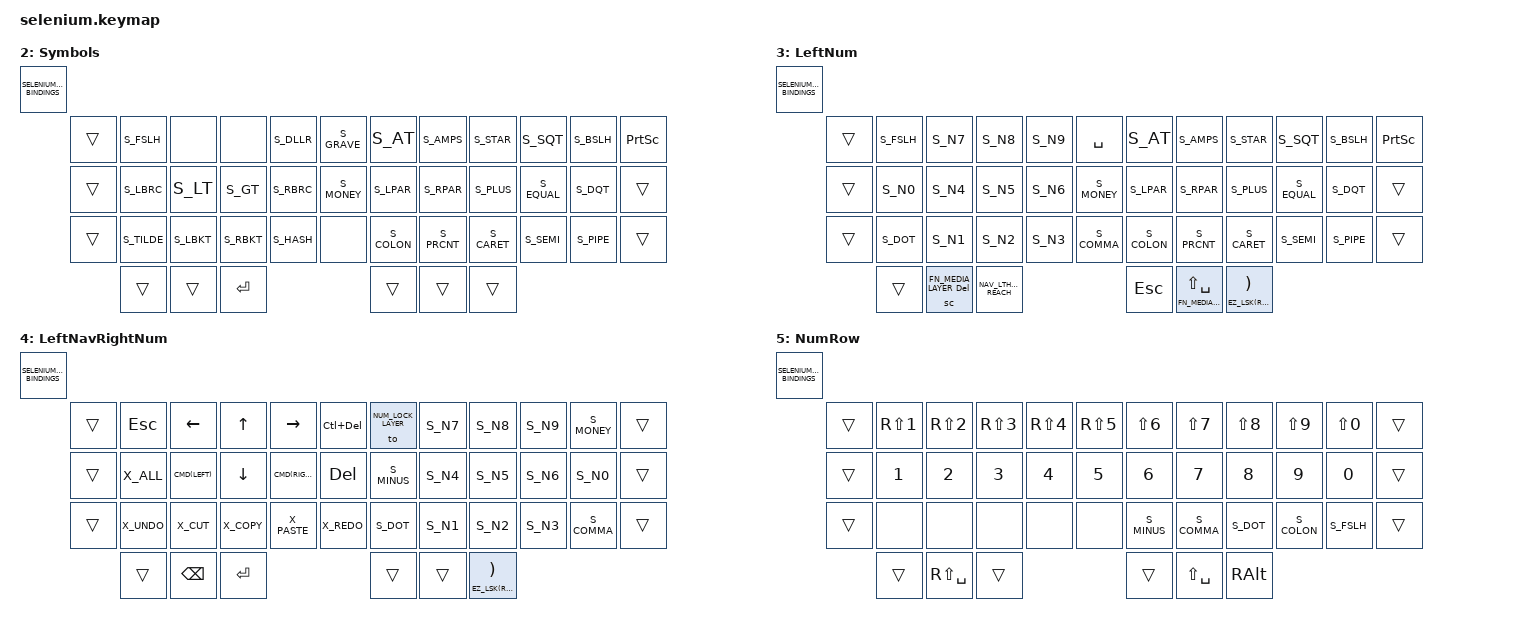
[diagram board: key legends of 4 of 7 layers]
// Selenium keymap:
// https://github.com/OneDeadKey/selenium

#include <dt-bindings/zmk/bt.h> // bluetooth behaviors (see fn/media layer)

#ifndef CI_IGNORE_USER_SETTINGS
  #include "settings.h"   // user settings
#endif

#include "defaults.h"     // default options and safeguards
#include "aliases.h"      // defines symbols and actions
#include "bindings.h"     // default SELENIUM_KEYMAP_BINDINGS macro
#include "mappings.dtsi"  // key mapping helpers and macros
#include "hold_taps.dtsi" // defines thumb keys and homerow mods

/**
 * All keyboard layers are defined by blocks on a 42-key basis, as follows:
 *
 *   <SELENIUM_KEYMAP_BINDINGS(
 *     Tab   , QWERT , YUIOP , BkSpc ,
 *     Esc   , ASDFG , HJKL: , Enter ,
 *     Shift , ZXCVB , NM<>? , Shift ,
 *      LT1, LT2, LT3, RT3, RT2, RT1
 *   )>
 *
 * Where LTx/RTx are the left/right thumb keys.
 * Beware: missing or misplacing a comma in the definitions below would break the keymap.
 */

/ {
  keymap {
    compatible = "zmk,keymap";

    // 0. Base layer -- keep the QWERTY key codes to use your OS keyboard layout
    //               -- the Space Cadet layer-tap on the right can be replaced by an AltGr/Enter mod-tap
    //               -- je m’habitue à ne plus utiliser le pouce gauche tuck, une fois la dispo maîtrisée je rajouterais probablement le layer fn
    base_layer: base_layer {
      display-name = "Base";
      bindings = <SELENIUM_KEYMAP_BINDINGS(
        &kp ESCAPE ,  &kp Q  &kp W  &kp E  &kp R  &kp T   ,   &kp Y  &kp U  &kp I     &kp O   &kp P     , &kp TAB ,
        &kp BACKSPACE ,  &lt NAV_LAYER A  HRM_S  HRM_D  HRM_F  &kp G   ,   &kp H  HRM_J  HRM_K     HRM_L   HRM_SEMI  ,  &meh_f1     ,
        &none ,  &kp Z  &kp X  &kp C  &kp V  &kp B   ,   &kp N  &kp M  &kp COMMA &kp DOT &kp FSLH  ,  &none    ,
               &lt SYMBOLS_LAYER SPACE, &sc VIM_NAV_LAYER BACKSPACE , &EZ_SK(LSHIFT)   ,   RTHUMB_REACH , &lt SYMBOLS_LAYER SPACE , RTHUMB_TUCK
      )>;
    };

    // 1. NumLock layer -- a NavNum layer that stays on until deactivated without holding any key
    num_lock_layer: num_lock_layer {
      display-name = "NumLock";
      bindings = <SELENIUM_KEYMAP_BINDINGS(
        &trans  ,  &kp ESC  &kp HOME &kp UP   &kp END   &kp PG_UP   ,   &to BASE_LAYER S_N7  S_N8  S_N9  S_FSLH  ,  &trans ,
        &trans  ,  S_EQUAL  &kp LEFT &kp DOWN &kp RIGHT &kp PG_DN   ,   S_MINUS        S_N4  S_N5  S_N6  S_N0    ,  &trans ,
        &trans  ,  S_MONEY  S_COLON  S_STAR   S_PLUS    S_PRCNT     ,   S_DOT        S_N1  S_N2  S_N3  S_COMMA   ,  &trans ,
                 &trans , &sc NAV_NUM_LAYER BACKSPACE , &kp (TAB)   ,   &trans , &lt NAV_NUM_LAYER LS(SPACE) , &EZ_SL(SYMBOLS_LAYER)
      )>;
    };

    // 2. Symbols layer -- with Ergol, basically just an AltGr layer with custom thumb keys
    //                  -- can be redefined for non-AltGr layouts such as QWERTY-ANSI
    symbols_layer: symbols_layer {
      display-name = "Symbols";
      bindings = <SELENIUM_KEYMAP_BINDINGS(
        &trans  ,  S_FSLH  &none &none S_DLLR  S_GRAVE   ,   S_AT    S_AMPS  S_STAR  S_SQT   S_BSLH  ,  &kp PSCRN ,
        &trans  ,  S_LBRC  S_LT  S_GT  S_RBRC  S_MONEY   ,   S_LPAR  S_RPAR  S_PLUS S_EQUAL  S_DQT    ,  &trans ,
        &trans  ,  S_TILDE S_LBKT  S_RBKT  S_HASH &none    ,   S_COLON  S_PRCNT  S_CARET  S_SEMI S_PIPE  ,  &trans ,
                     &trans , &trans , &kp ENTER   ,   &trans ,  &trans ,  &trans
      )>;
    };

    // 3. LeftNum - je ne sais pas encore ce que je fais avec la partie de droite, peut-être du controle médias, des smileys
    vim_nav_layer: vim_nav_layer {
      display-name = "LeftNum";
      bindings = <SELENIUM_KEYMAP_BINDINGS(
        &trans  ,  S_FSLH             S_N7  S_N8  S_N9  &kp SPACE ,   S_AT    S_AMPS  S_STAR  S_SQT   S_BSLH  ,  &kp PSCRN ,
        &trans  ,  S_N0            S_N4  S_N5  S_N6  S_MONEY  ,   S_LPAR  S_RPAR  S_PLUS S_EQUAL  S_DQT    ,  &trans ,
        &trans  ,  S_DOT            S_N1  S_N2  S_N3  S_COMMA ,  S_COLON  S_PRCNT  S_CARET  S_SEMI S_PIPE   ,  &trans ,
      &trans , &sc FN_MEDIA_LAYER DEL , NAV_LTHUMB_REACH   ,   &kp ESCAPE , &lt FN_MEDIA_LAYER LS(SPACE) , &EZ_LSK(RALT)
      )>;
    };

    // 4. LeftNavRightNum - le pouce gauche à accès aux touches espace et entrée en mirroir du pouce droit
    //                    -- la partie de droite pourrait être remplacée pour autre chose comme du controle de la souris. 
    //                    -- À terme, soit je garde le pavé numérique en miroir soit j’ai deux layers avec la partie droite du clavier de disponible
    nav_num_layer: nav_num_layer {
      display-name = "LeftNavRightNum";
      bindings = <SELENIUM_KEYMAP_BINDINGS(
        &trans  ,  &kp ESC  &kp LEFT &kp UP   &kp RIGHT   &kp LC(DEL)   ,   &to NUM_LOCK_LAYER S_N7  S_N8  S_N9  S_MONEY  ,  &trans ,
        &trans  ,  X_ALL    &kp CMD(LEFT) &kp DOWN  &kp CMD(RIGHT)  &kp DEL   ,   S_MINUS            S_N4  S_N5  S_N6  S_N0    ,  &trans ,
        &trans  ,  X_UNDO   X_CUT    X_COPY   X_PASTE   X_REDO      ,   S_DOT            S_N1  S_N2  S_N3  S_COMMA   ,  &trans ,
      &trans , &kp BACKSPACE , &kp ENTER   ,   &trans , &trans , &EZ_LSK(RALT)
      )>;
    };

    // 5. NumRow layer -- bring the numbers to the homerow, keep shift+numbers for shortcuts and symbols
    //                 -- space becomes shift+space, which is a no-break space with some OS layouts (e.g. Ergol)
    //                 -- best used along with the VimNav layer
    num_row_layer: num_row_layer {
      display-name = "NumRow";
      bindings = <SELENIUM_KEYMAP_BINDINGS(
        &trans  ,  &kp RS(N1) &kp RS(N2) &kp RS(N3) &kp RS(N4) &kp RS(N5)   ,   &kp LS(N6) &kp LS(N7) &kp LS(N8) &kp LS(N9) &kp LS(N0)  ,  &trans ,
        &trans  ,  &kp N1     &kp N2     &kp N3     &kp N4     &kp N5       ,   &kp N6     &kp N7     &kp N8     &kp N9     &kp N0      ,  &trans ,
        &trans  ,  &none      &none      &none      &none      &none        ,   S_MINUS    S_COMMA    S_DOT      S_COLON    S_FSLH      ,  &trans ,
                                      &trans , &kp RS(SPACE) , &trans       ,   &trans , &kp LS(SPACE) , &kp RALT
      )>;
    };

    // 6. FnMedia layer -- F1..12 pad on the left hand, HRM on the right hand
    //                  -- reset and bootloader reset on difficult thumb keys
    //                  -- could be completed with other rare keys
    fn_media_layer: fn_media_layer {
      display-name = "FnMedia";
      bindings = <SELENIUM_KEYMAP_BINDINGS(
        &trans  ,  &none &kp C_BRI_UP  &kp C_VOL_UP  &kp C_NEXT  &trans   ,   &kp F7  &kp F8  &kp F9  &kp F12   &trans      ,  &trans ,
        &trans  ,  &none  &none  H_K C_MUTE  H_J C_PP  &trans   ,   &trans  &kp F4  &kp F5  &kp F6  &kp F11  ,  &trans ,
        &trans  ,  &none  &kp C_BRI_DN &kp C_VOL_DN &kp C_PREV &trans   ,   &trans &kp F1 &kp F2 &kp F3 &kp F10       ,  &trans ,
                           &trans , &trans , &trans   ,   &trans , &trans , &studio_unlock
      )>;
    };

  };
};

// Emulated layouts (experimental!)
#ifdef KB_EMULATION_DVORAK
  #include "emulations/dvorak.dtsi"
#elif defined KB_EMULATION_ERGOL
  #include "emulations/ergol.dtsi"
#elif defined KB_EMULATION_QWERTY_LAFAYETTE
  #include "emulations/qwerty_lafayette.dtsi"

// Some layouts require extra layers to fit on the Quacken.
#elif defined KB_LAYOUT_AZERTY
  #include "extra_layers/azerty.dtsi"
#elif defined KB_LAYOUT_BEPO
  #include "extra_layers/bepo.dtsi"
#elif defined KB_LAYOUT_ERGOL && defined HUMMINGBIRD
  #include "extra_layers/ergol_hummingbird.dtsi"
#endif
